VERSION ""

NS_ :

BS_:

BU_: XXX

BO_ 80 BODY_CONTROL_STATE: 8 XXX
 SG_ SEATBELT_DRIVER_UNLATCHED : 14|1@0+ (1,0) [0|1] "" XXX

BO_ 368 STEER_TORQUE_SENSOR_2: 8 XXX
 SG_ STEER_TORQUE_EPS : 7|16@0- (1,0) [0|0] "" XXX

BO_ 378 VEHICLE_SPEED: 8 XXX
 SG_ VEHICLE_SPEED : 39|16@0+ (0.05,0) [0|250] "km/h" XXX

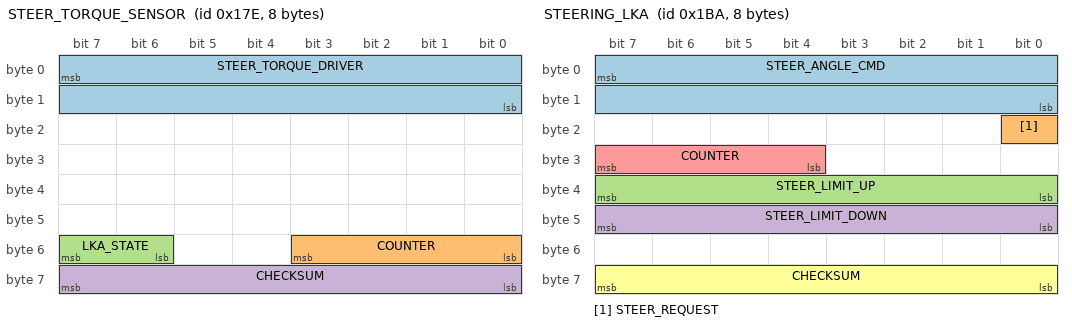
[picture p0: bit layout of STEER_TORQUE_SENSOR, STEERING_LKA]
BO_ 382 STEER_TORQUE_SENSOR: 8 XXX
 SG_ STEER_TORQUE_DRIVER : 7|16@0- (0.01,0) [0|0] "" XXX
 SG_ COUNTER : 51|4@0+ (1,0) [0|15] "" XXX
 SG_ LKA_STATE : 55|2@0+ (1,0) [0|3] "" XXX
 SG_ CHECKSUM : 63|8@0+ (1,0) [0|255] "" XXX

BO_ 384 STEER_ANGLE_SENSOR: 8 XXX
 SG_ STEER_ANGLE : 7|16@0- (0.1,0) [-476|476] "deg" XXX
 SG_ STEER_RATE : 23|16@0- (1,0) [0|0] "deg/s" XXX

BO_ 391 WHEEL_SPEEDS: 8 XXX
 SG_ WHEEL_SPEED_FL : 39|16@0+ (0.05,0) [0|65535] "km/h" XXX

BO_ 406 BRAKE_MODULE: 8 XXX
 SG_ BRAKE_PRESSED : 0|1@0+ (1,0) [0|1] "" XXX
 SG_ GAS_PEDAL_USER : 15|8@0+ (1,0) [0|0] "" XXX

BO_ 422 BRAKE_MODULE_ALT: 8 XXX
 SG_ BRAKE_PRESSED : 0|1@0+ (1,0) [0|1] "" XXX
 SG_ BRAKE : 31|8@0+ (1,0) [0|255] "" XXX

BO_ 442 STEERING_LKA: 8 XXX
 SG_ STEER_ANGLE_CMD : 7|16@0- (0.1,0) [0|0] "deg" XXX
 SG_ STEER_REQUEST : 16|1@0+ (1,0) [0|1] "" XXX
 SG_ STEER_LIMIT_UP : 39|8@0+ (0.1,0) [0|25.5] "" XXX
 SG_ STEER_LIMIT_DOWN : 47|8@0+ (0.1,-12.8) [-12.8|12.7] "" XXX
 SG_ COUNTER : 31|4@0+ (1,0) [0|15] "" XXX
 SG_ CHECKSUM : 63|8@0+ (1,0) [0|255] "" XXX

BO_ 454 GAS_PEDAL_ALT: 8 XXX
 SG_ GAS_PEDAL_USER : 7|8@0+ (1,0) [0|0] "" XXX

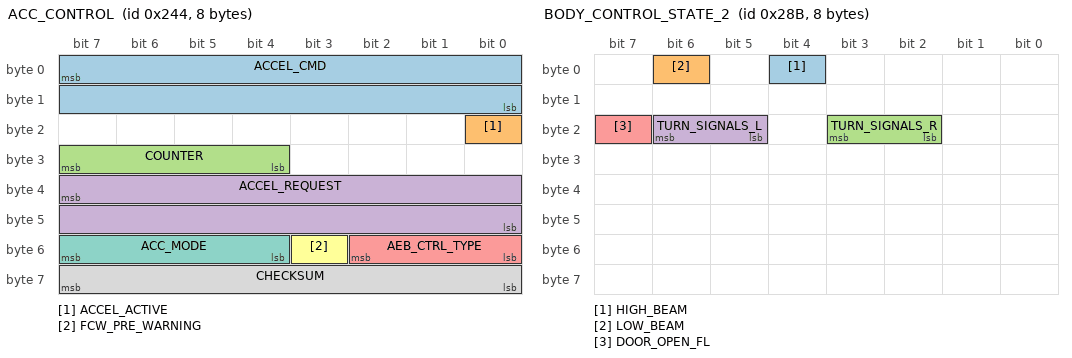
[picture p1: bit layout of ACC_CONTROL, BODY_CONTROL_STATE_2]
BO_ 580 ACC_CONTROL: 8 XXX
 SG_ ACCEL_CMD : 7|16@0- (0.001,0) [-20|20] "m/s^2" XXX
 SG_ ACCEL_ACTIVE : 16|1@0+ (1,0) [0|1] "" XXX
 SG_ COUNTER : 31|4@0+ (1,0) [0|15] "" XXX
 SG_ ACCEL_REQUEST : 39|16@0- (1,0) [0|0] "" XXX
 SG_ AEB_CTRL_TYPE : 50|3@0+ (1,0) [0|7] "" XXX
 SG_ FCW_PRE_WARNING : 51|1@0+ (1,0) [0|1] "" XXX
 SG_ ACC_MODE : 55|4@0+ (1,0) [0|15] "" XXX
 SG_ CHECKSUM : 63|8@0+ (1,0) [0|255] "" XXX

BO_ 591 EPS_STATUS: 8 XXX
 SG_ EPS_FAILED : 0|1@0+ (1,0) [0|1] "" XXX

BO_ 631 BRAKE_MAYBE: 8 XXX
 SG_ BRAKE_MAYBE : 7|1@0+ (1,0) [0|1] "" XXX

BO_ 651 BODY_CONTROL_STATE_2: 8 XXX
 SG_ HIGH_BEAM : 4|1@0+ (1,0) [0|1] "" XXX
 SG_ LOW_BEAM : 6|1@0+ (1,0) [0|1] "" XXX
 SG_ TURN_SIGNALS_R : 19|2@0+ (1,0) [0|3] "" XXX
 SG_ TURN_SIGNALS_L : 22|2@0+ (1,0) [0|3] "" XXX
 SG_ DOOR_OPEN_FL : 23|1@0+ (1,0) [0|1] "" XXX

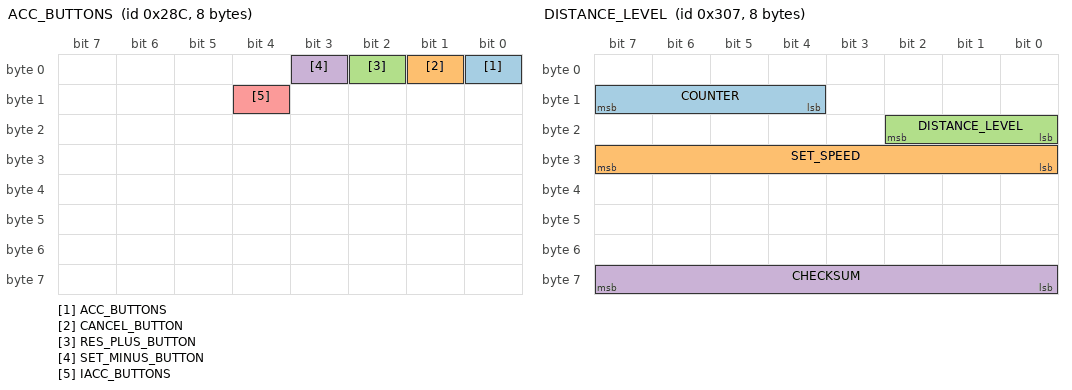
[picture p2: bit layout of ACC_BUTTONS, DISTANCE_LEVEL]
BO_ 652 ACC_BUTTONS: 8 XXX
 SG_ ACC_BUTTONS : 0|1@0+ (1,0) [0|1] "" XXX
 SG_ CANCEL_BUTTON : 1|1@0+ (1,0) [0|1] "" XXX
 SG_ RES_PLUS_BUTTON : 2|1@0+ (1,0) [0|1] "" XXX
 SG_ SET_MINUS_BUTTON : 3|1@0+ (1,0) [0|1] "" XXX
 SG_ IACC_BUTTONS : 12|1@0+ (1,0) [0|1] "" XXX

BO_ 775 DISTANCE_LEVEL: 8 XXX
 SG_ COUNTER : 15|4@0+ (1,0) [0|15] "" XXX
 SG_ SET_SPEED : 31|8@0+ (1,0) [0|255] "km/h" XXX
 SG_ DISTANCE_LEVEL : 18|3@0+ (1,0) [0|7] "" XXX
 SG_ CHECKSUM : 63|8@0+ (1,0) [0|255] "" XXX

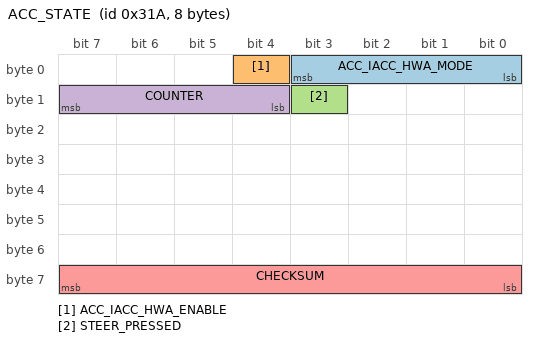
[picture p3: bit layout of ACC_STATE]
BO_ 794 ACC_STATE: 8 XXX
 SG_ ACC_IACC_HWA_MODE : 3|4@0+ (1,0) [0|15] "" XXX
 SG_ ACC_IACC_HWA_ENABLE : 4|1@0+ (1,0) [0|1] "" XXX
 SG_ STEER_PRESSED : 11|1@0+ (1,0) [0|1] "" XXX
 SG_ COUNTER : 15|4@0+ (1,0) [0|15] "" XXX
 SG_ CHECKSUM : 63|8@0+ (1,0) [0|255] "" XXX

BO_ 824 GEAR_PACKET: 8 XXX
 SG_ GEAR : 39|4@0+ (1,-7) [0|15] "" XXX

CM_ SG_ 384 STEER_ANGLE "1";
VAL_ 824 GEAR 2 "N" 1 "R" 3 "D" 0 "P";
